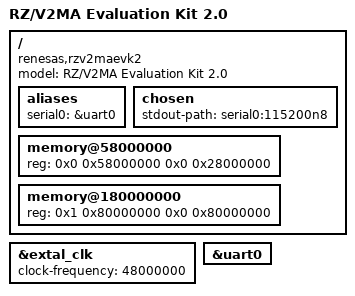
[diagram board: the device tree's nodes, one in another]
// SPDX-License-Identifier: (GPL-2.0-only OR BSD-2-Clause)
/*
 * Device Tree Source for the RZ/V2MA (r9a09g055) Evaluation Kit Board
 *
 * Copyright (C) 2022 Renesas Electronics Corp.
 */

/dts-v1/;
#include "r9a09g055.dtsi"

/ {
	model = "RZ/V2MA Evaluation Kit 2.0";
	compatible = "renesas,rzv2maevk2", "renesas,r9a09g055";

	aliases {
		serial0 = &uart0;
	};

	chosen {
		stdout-path = "serial0:115200n8";
	};

	memory@58000000 {
		device_type = "memory";
		/*
		 * first 1.25GiB is reserved for ISP Firmware,
		 * next 128MiB is reserved for secure area.
		 */
		reg = <0x0 0x58000000 0x0 0x28000000>;
	};

	memory@180000000 {
		device_type = "memory";
		reg = <0x1 0x80000000 0x0 0x80000000>;
	};
};

&extal_clk {
	clock-frequency = <48000000>;
};

&uart0 {
	status = "okay";
};
